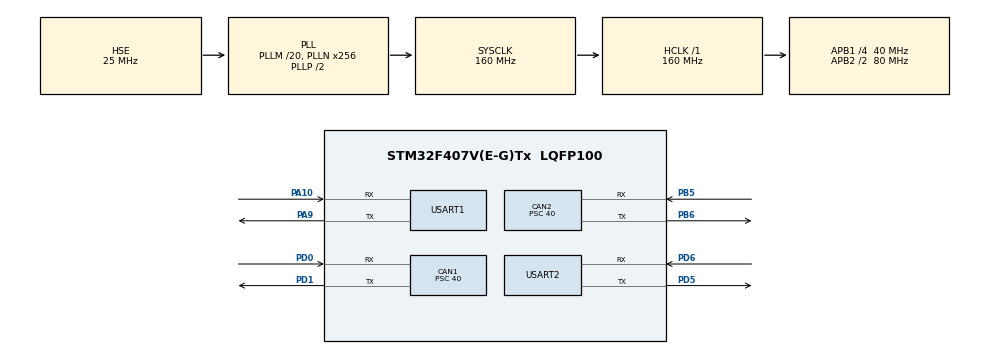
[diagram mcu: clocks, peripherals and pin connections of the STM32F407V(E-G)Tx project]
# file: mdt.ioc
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CAN1.BS1=CAN_BS1_1TQ
CAN1.BS2=CAN_BS2_1TQ
CAN1.CalculateTimeQuantum=1000.0
CAN1.Prescaler=40
CAN2.BS1=CAN_BS1_1TQ
CAN2.BS2=CAN_BS2_1TQ
CAN2.CalculateTimeQuantum=1000.0
CAN2.Prescaler=40
Mcu.Family=STM32F4
Mcu.Name=STM32F407V(E-G)Tx
Mcu.Package=LQFP100
NVIC.CAN1_RX0_IRQn=true\:0\:0\:false\:false\:true\:true\:true
NVIC.CAN1_RX1_IRQn=true\:0\:0\:false\:false\:true\:true\:true
NVIC.CAN1_TX_IRQn=true\:0\:0\:false\:false\:true\:true\:true
NVIC.CAN2_RX0_IRQn=true\:0\:0\:false\:false\:true\:true\:true
NVIC.CAN2_RX1_IRQn=true\:0\:0\:false\:false\:true\:true\:true
NVIC.CAN2_TX_IRQn=true\:0\:0\:false\:false\:true\:true\:true
NVIC.PriorityGroup=NVIC_PRIORITYGROUP_4
NVIC.USART1_IRQn=true\:0\:0\:false\:false\:true\:true\:true
NVIC.USART2_IRQn=true\:0\:0\:false\:false\:true\:true\:true
PA10.Mode=Asynchronous
PA10.Signal=USART1_RX
PA13.Mode=JTAG_5_pins
PA13.Signal=SYS_JTMS-SWDIO
PA14.Mode=JTAG_5_pins
PA14.Signal=SYS_JTCK-SWCLK
PA15.Mode=JTAG_5_pins
PA15.Signal=SYS_JTDI
PA9.Mode=Asynchronous
PA9.Signal=USART1_TX
PB3.Mode=JTAG_5_pins
PB3.Signal=SYS_JTDO-SWO
PB4.Mode=JTAG_5_pins
PB4.Signal=SYS_JTRST
PB5.Mode=Slave
PB5.Signal=CAN2_RX
PB6.Mode=Slave
PB6.Signal=CAN2_TX
PD0.Mode=Master
PD0.Signal=CAN1_RX
PD1.Mode=Master
PD1.Signal=CAN1_TX
PD5.Mode=Asynchronous
PD5.Signal=USART2_TX
PD6.Mode=Asynchronous
PD6.Signal=USART2_RX
PH0-OSC_IN.Mode=HSE-External-Oscillator
PH0-OSC_IN.Signal=RCC_OSC_IN
PH1-OSC_OUT.Mode=HSE-External-Oscillator
PH1-OSC_OUT.Signal=RCC_OSC_OUT
ProjectManager.HeapSize=0x1000
ProjectManager.StackSize=0x1000
ProjectManager.TargetToolchain=MDK-ARM V5
RCC.48MHZClocksFreq_Value=80000000
RCC.AHBFreq_Value=160000000
RCC.APB1CLKDivider=RCC_HCLK_DIV4
RCC.APB1Freq_Value=40000000
RCC.APB1TimFreq_Value=80000000
RCC.APB2CLKDivider=RCC_HCLK_DIV2
RCC.APB2Freq_Value=80000000
RCC.APB2TimFreq_Value=160000000
RCC.CortexFreq_Value=160000000
RCC.HCLKFreq_Value=160000000
RCC.HSE_VALUE=25000000
RCC.HSI_VALUE=16000000
RCC.LSE_VALUE=32768
RCC.PLLM=20
RCC.PLLN=256
RCC.PLLSourceVirtual=RCC_PLLSOURCE_HSE
RCC.SYSCLKFreq_VALUE=160000000
RCC.SYSCLKSource=RCC_SYSCLKSOURCE_PLLCLK
RCC.VCOOutputFreq_Value=320000000
USART1.VirtualMode=VM_ASYNC
USART2.VirtualMode=VM_ASYNC
board=custom

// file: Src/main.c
/* USER CODE BEGIN Header */
/**
  ******************************************************************************
  * @file           : main.c
  * @brief          : Main program body
  ******************************************************************************
  * @attention
  *
  * <h2><center>&copy; Copyright (c) 2020 STMicroelectronics.
  * All rights reserved.</center></h2>
  *
  * This software component is licensed by ST under BSD 3-Clause license,
  * the "License"; You may not use this file except in compliance with the
  * License. You may obtain a copy of the License at:
  *                        opensource.org/licenses/BSD-3-Clause
  *
  ******************************************************************************
  */
/* USER CODE END Header */

#include "main.h"

/* USER CODE BEGIN Includes */
#include "uart.h"
#include "can.h"
/* USER CODE END Includes */

CAN_HandleTypeDef hcan1;
CAN_HandleTypeDef hcan2;

UART_HandleTypeDef huart1;
UART_HandleTypeDef huart2;

/* USER CODE BEGIN PV */
extern Uart_TR Uart_TR1;
extern Uart_TR Uart_TR2;
/* USER CODE END PV */

void SystemClock_Config(void);
static void MX_GPIO_Init(void);
static void MX_CAN1_Init(void);
static void MX_CAN2_Init(void);
static void MX_USART1_UART_Init(void);
static void MX_USART2_UART_Init(void);

int main(void)
{
  /* USER CODE BEGIN 1 */
	unsigned char i;
  /* USER CODE END 1 */

  /* MCU Configuration--------------------------------------------------------*/

  /* Reset of all peripherals, Initializes the Flash interface and the Systick. */
  HAL_Init();

  /* Configure the system clock */
  SystemClock_Config();

  /* USER CODE BEGIN SysInit */
	SystemCoreClockUpdate();
  /* USER CODE END SysInit */

  /* Initialize all configured peripherals */
  MX_GPIO_Init();
  MX_CAN1_Init();
  MX_CAN2_Init();
  MX_USART1_UART_Init();
  MX_USART2_UART_Init();
  /* USER CODE BEGIN 2 */
	UART_InitTR();
	UART_ActiveReceive(&Uart_TR1);
  /* USER CODE END 2 */

  /* Infinite loop */
  while (1)
  {
		while(UART_IsTxIDLE(&Uart_TR1))
		{
			Uart_TR1.size = 20;
			for(i=0;i<Uart_TR1.size;i++)
				Uart_TR1.BUF[i] = i;
			UART_Transmit(&Uart_TR1);
		}
  }
}

void SystemClock_Config(void)
{
  RCC_OscInitTypeDef RCC_OscInitStruct = {0};
  RCC_ClkInitTypeDef RCC_ClkInitStruct = {0};

  /** Configure the main internal regulator output voltage
  */
  __HAL_RCC_PWR_CLK_ENABLE();
  __HAL_PWR_VOLTAGESCALING_CONFIG(PWR_REGULATOR_VOLTAGE_SCALE1);
  /** Initializes the CPU, AHB and APB busses clocks
  */
  RCC_OscInitStruct.OscillatorType = RCC_OSCILLATORTYPE_HSE;
  RCC_OscInitStruct.HSEState = RCC_HSE_ON;
  RCC_OscInitStruct.PLL.PLLState = RCC_PLL_ON;
  RCC_OscInitStruct.PLL.PLLSource = RCC_PLLSOURCE_HSE;
  RCC_OscInitStruct.PLL.PLLM = 20;
  RCC_OscInitStruct.PLL.PLLN = 256;
  RCC_OscInitStruct.PLL.PLLP = RCC_PLLP_DIV2;
  RCC_OscInitStruct.PLL.PLLQ = 4;
  if (HAL_RCC_OscConfig(&RCC_OscInitStruct) != HAL_OK)
  {
    Error_Handler();
  }
  /** Initializes the CPU, AHB and APB busses clocks
  */
  RCC_ClkInitStruct.ClockType = RCC_CLOCKTYPE_HCLK|RCC_CLOCKTYPE_SYSCLK
                              |RCC_CLOCKTYPE_PCLK1|RCC_CLOCKTYPE_PCLK2;
  RCC_ClkInitStruct.SYSCLKSource = RCC_SYSCLKSOURCE_PLLCLK;
  RCC_ClkInitStruct.AHBCLKDivider = RCC_SYSCLK_DIV1;
  RCC_ClkInitStruct.APB1CLKDivider = RCC_HCLK_DIV4;
  RCC_ClkInitStruct.APB2CLKDivider = RCC_HCLK_DIV2;

  if (HAL_RCC_ClockConfig(&RCC_ClkInitStruct, FLASH_LATENCY_5) != HAL_OK)
  {
    Error_Handler();
  }
}

static void MX_CAN1_Init(void)
{

  hcan1.Instance = CAN1;
  hcan1.Init.Prescaler = 40;
  hcan1.Init.Mode = CAN_MODE_NORMAL;
  hcan1.Init.SyncJumpWidth = CAN_SJW_1TQ;
  hcan1.Init.TimeSeg1 = CAN_BS1_1TQ;
  hcan1.Init.TimeSeg2 = CAN_BS2_1TQ;
  hcan1.Init.TimeTriggeredMode = DISABLE;
  hcan1.Init.AutoBusOff = DISABLE;
  hcan1.Init.AutoWakeUp = DISABLE;
  hcan1.Init.AutoRetransmission = DISABLE;
  hcan1.Init.ReceiveFifoLocked = DISABLE;
  hcan1.Init.TransmitFifoPriority = DISABLE;
  if (HAL_CAN_Init(&hcan1) != HAL_OK)
  {
    Error_Handler();
  }

}

static void MX_CAN2_Init(void)
{

  hcan2.Instance = CAN2;
  hcan2.Init.Prescaler = 40;
  hcan2.Init.Mode = CAN_MODE_NORMAL;
  hcan2.Init.SyncJumpWidth = CAN_SJW_1TQ;
  hcan2.Init.TimeSeg1 = CAN_BS1_1TQ;
  hcan2.Init.TimeSeg2 = CAN_BS2_1TQ;
  hcan2.Init.TimeTriggeredMode = DISABLE;
  hcan2.Init.AutoBusOff = DISABLE;
  hcan2.Init.AutoWakeUp = DISABLE;
  hcan2.Init.AutoRetransmission = DISABLE;
  hcan2.Init.ReceiveFifoLocked = DISABLE;
  hcan2.Init.TransmitFifoPriority = DISABLE;
  if (HAL_CAN_Init(&hcan2) != HAL_OK)
  {
    Error_Handler();
  }

}

static void MX_USART1_UART_Init(void)
{

  huart1.Instance = USART1;
  huart1.Init.BaudRate = 115200;
  huart1.Init.WordLength = UART_WORDLENGTH_8B;
  huart1.Init.StopBits = UART_STOPBITS_1;
  huart1.Init.Parity = UART_PARITY_NONE;
  huart1.Init.Mode = UART_MODE_TX_RX;
  huart1.Init.HwFlowCtl = UART_HWCONTROL_NONE;
  huart1.Init.OverSampling = UART_OVERSAMPLING_16;
  if (HAL_UART_Init(&huart1) != HAL_OK)
  {
    Error_Handler();
  }

}

static void MX_USART2_UART_Init(void)
{

  huart2.Instance = USART2;
  huart2.Init.BaudRate = 115200;
  huart2.Init.WordLength = UART_WORDLENGTH_8B;
  huart2.Init.StopBits = UART_STOPBITS_1;
  huart2.Init.Parity = UART_PARITY_NONE;
  huart2.Init.Mode = UART_MODE_TX_RX;
  huart2.Init.HwFlowCtl = UART_HWCONTROL_NONE;
  huart2.Init.OverSampling = UART_OVERSAMPLING_16;
  if (HAL_UART_Init(&huart2) != HAL_OK)
  {
    Error_Handler();
  }

}

static void MX_GPIO_Init(void)
{

  /* GPIO Ports Clock Enable */
  __HAL_RCC_GPIOH_CLK_ENABLE();
  __HAL_RCC_GPIOA_CLK_ENABLE();
  __HAL_RCC_GPIOD_CLK_ENABLE();
  __HAL_RCC_GPIOB_CLK_ENABLE();

}

void Error_Handler(void)
{
}

/************************ (C) COPYRIGHT STMicroelectronics *****END OF FILE****/
